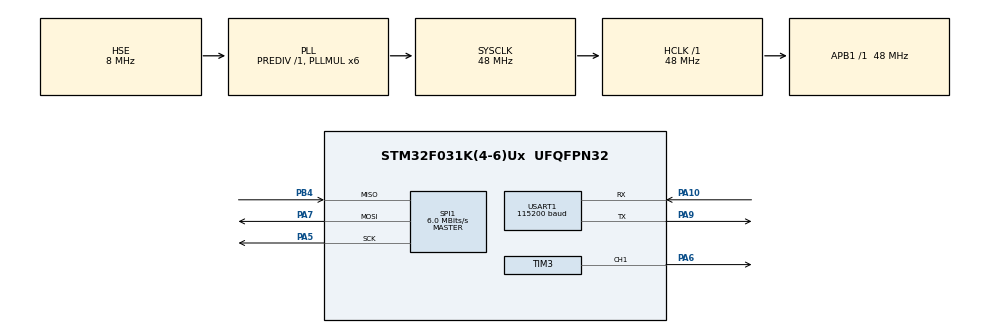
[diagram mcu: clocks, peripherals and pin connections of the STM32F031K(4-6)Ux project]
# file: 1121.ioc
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Dma.Request0=USART1_RX
Dma.Request1=USART1_TX
Dma.Request2=SPI1_TX
Dma.SPI1_TX.2.Direction=DMA_MEMORY_TO_PERIPH
Dma.SPI1_TX.2.Instance=DMA1_Channel3
Dma.SPI1_TX.2.MemDataAlignment=DMA_MDATAALIGN_BYTE
Dma.SPI1_TX.2.MemInc=DMA_MINC_ENABLE
Dma.SPI1_TX.2.Mode=DMA_NORMAL
Dma.SPI1_TX.2.PeriphDataAlignment=DMA_PDATAALIGN_BYTE
Dma.SPI1_TX.2.PeriphInc=DMA_PINC_DISABLE
Dma.SPI1_TX.2.Priority=DMA_PRIORITY_LOW
Dma.USART1_RX.0.Direction=DMA_PERIPH_TO_MEMORY
Dma.USART1_RX.0.Instance=DMA1_Channel5
Dma.USART1_RX.0.MemDataAlignment=DMA_MDATAALIGN_BYTE
Dma.USART1_RX.0.MemInc=DMA_MINC_ENABLE
Dma.USART1_RX.0.Mode=DMA_NORMAL
Dma.USART1_RX.0.PeriphDataAlignment=DMA_PDATAALIGN_BYTE
Dma.USART1_RX.0.PeriphInc=DMA_PINC_DISABLE
Dma.USART1_RX.0.Priority=DMA_PRIORITY_LOW
Dma.USART1_TX.1.Direction=DMA_MEMORY_TO_PERIPH
Dma.USART1_TX.1.Instance=DMA1_Channel4
Dma.USART1_TX.1.MemDataAlignment=DMA_MDATAALIGN_BYTE
Dma.USART1_TX.1.MemInc=DMA_MINC_ENABLE
Dma.USART1_TX.1.Mode=DMA_NORMAL
Dma.USART1_TX.1.PeriphDataAlignment=DMA_PDATAALIGN_BYTE
Dma.USART1_TX.1.PeriphInc=DMA_PINC_DISABLE
Dma.USART1_TX.1.Priority=DMA_PRIORITY_LOW
Mcu.Family=STM32F0
Mcu.Name=STM32F031K(4-6)Ux
Mcu.Package=UFQFPN32
NVIC.DMA1_Channel2_3_IRQn=true\:0\:0\:false\:false\:true\:false\:true\:true
NVIC.DMA1_Channel4_5_IRQn=true\:0\:0\:false\:false\:true\:false\:true\:true
NVIC.USART1_IRQn=true\:0\:0\:false\:false\:true\:true\:true\:true
PA10.Mode=Asynchronous
PA10.Signal=USART1_RX
PA13.Mode=Serial_Wire
PA13.Signal=SYS_SWDIO
PA14.Mode=Serial_Wire
PA14.Signal=SYS_SWCLK
PA5.Mode=Full_Duplex_Master
PA5.Signal=SPI1_SCK
PA6.Signal=S_TIM3_CH1
PA7.Mode=Full_Duplex_Master
PA7.Signal=SPI1_MOSI
PA9.Mode=Asynchronous
PA9.Signal=USART1_TX
PB4.Mode=Full_Duplex_Master
PB4.Signal=SPI1_MISO
PF0-OSC_IN.Mode=HSE-External-Oscillator
PF0-OSC_IN.Signal=RCC_OSC_IN
PF1-OSC_OUT.Mode=HSE-External-Oscillator
PF1-OSC_OUT.Signal=RCC_OSC_OUT
ProjectManager.HeapSize=0x200
ProjectManager.StackSize=0x400
ProjectManager.TargetToolchain=MDK-ARM V5.32
RCC.AHBFreq_Value=48000000
RCC.APB1Freq_Value=48000000
RCC.APB1TimFreq_Value=48000000
RCC.HCLKFreq_Value=48000000
RCC.PLLMUL=RCC_PLL_MUL6
RCC.PLLSourceVirtual=RCC_PLLSOURCE_HSE
RCC.SYSCLKFreq_VALUE=48000000
RCC.SYSCLKSource=RCC_SYSCLKSOURCE_PLLCLK
SH.S_TIM3_CH1.0=TIM3_CH1,PWM Generation1 CH1
SPI1.BaudRatePrescaler=SPI_BAUDRATEPRESCALER_8
SPI1.CLKPhase=SPI_PHASE_2EDGE
SPI1.CLKPolarity=SPI_POLARITY_HIGH
SPI1.CalculateBaudRate=6.0 MBits/s
SPI1.DataSize=SPI_DATASIZE_8BIT
SPI1.Direction=SPI_DIRECTION_2LINES
SPI1.Mode=SPI_MODE_MASTER
SPI1.VirtualType=VM_MASTER
TIM3.AutoReloadPreload=TIM_AUTORELOAD_PRELOAD_ENABLE
TIM3.Channel-PWM\ Generation1\ CH1=TIM_CHANNEL_1
TIM3.Period=20000
TIM3.Prescaler=48
USART1.BaudRate=115200
USART1.VirtualMode-Asynchronous=VM_ASYNC
board=custom

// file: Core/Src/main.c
/* USER CODE BEGIN Header */
/**
  ******************************************************************************
  * @file           : main.c
  * @brief          : Main program body
  ******************************************************************************
  * @attention
  *
  * Copyright (c) 2023 STMicroelectronics.
  * All rights reserved.
  *
  * This software is licensed under terms that can be found in the LICENSE file
  * in the root directory of this software component.
  * If no LICENSE file comes with this software, it is provided AS-IS.
  *
  ******************************************************************************
  */
/* USER CODE END Header */
#include "main.h"
#include "dma.h"
#include "spi.h"
#include "tim.h"
#include "usart.h"
#include "gpio.h"
#include "ws2812B.h"

void SystemClock_Config(void);

int main(void)
{

  /* MCU Configuration--------------------------------------------------------*/

  /* Reset of all peripherals, Initializes the Flash interface and the Systick. */
  HAL_Init();

  /* Configure the system clock */
  SystemClock_Config();

  /* Initialize all configured peripherals */
  MX_GPIO_Init();
  MX_DMA_Init();
  MX_USART1_UART_Init();
  MX_SPI1_Init();
  MX_TIM3_Init();
  /* USER CODE BEGIN 2 */
  init_Config();
  /* USER CODE END 2 */

  /* Infinite loop */
  /* USER CODE BEGIN WHILE */
  while (1)
  {
		if(breathFlag == 1) {
			breatheLED();
		}
	}
    /* USER CODE END WHILE */

}

void SystemClock_Config(void)
{
  RCC_OscInitTypeDef RCC_OscInitStruct = {0};
  RCC_ClkInitTypeDef RCC_ClkInitStruct = {0};
  RCC_PeriphCLKInitTypeDef PeriphClkInit = {0};

  /** Initializes the RCC Oscillators according to the specified parameters
  * in the RCC_OscInitTypeDef structure.
  */
  RCC_OscInitStruct.OscillatorType = RCC_OSCILLATORTYPE_HSE;
  RCC_OscInitStruct.HSEState = RCC_HSE_ON;
  RCC_OscInitStruct.PLL.PLLState = RCC_PLL_ON;
  RCC_OscInitStruct.PLL.PLLSource = RCC_PLLSOURCE_HSE;
  RCC_OscInitStruct.PLL.PLLMUL = RCC_PLL_MUL6;
  RCC_OscInitStruct.PLL.PREDIV = RCC_PREDIV_DIV1;
  if (HAL_RCC_OscConfig(&RCC_OscInitStruct) != HAL_OK)
  {
    Error_Handler();
  }

  /** Initializes the CPU, AHB and APB buses clocks
  */
  RCC_ClkInitStruct.ClockType = RCC_CLOCKTYPE_HCLK|RCC_CLOCKTYPE_SYSCLK
                              |RCC_CLOCKTYPE_PCLK1;
  RCC_ClkInitStruct.SYSCLKSource = RCC_SYSCLKSOURCE_PLLCLK;
  RCC_ClkInitStruct.AHBCLKDivider = RCC_SYSCLK_DIV1;
  RCC_ClkInitStruct.APB1CLKDivider = RCC_HCLK_DIV1;

  if (HAL_RCC_ClockConfig(&RCC_ClkInitStruct, FLASH_LATENCY_1) != HAL_OK)
  {
    Error_Handler();
  }
  PeriphClkInit.PeriphClockSelection = RCC_PERIPHCLK_USART1;
  PeriphClkInit.Usart1ClockSelection = RCC_USART1CLKSOURCE_PCLK1;
  if (HAL_RCCEx_PeriphCLKConfig(&PeriphClkInit) != HAL_OK)
  {
    Error_Handler();
  }
}

void Error_Handler(void)
{
  __disable_irq();
  while (1)
  {
  }
}
